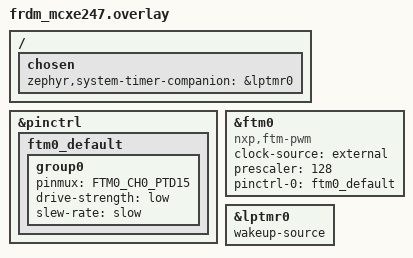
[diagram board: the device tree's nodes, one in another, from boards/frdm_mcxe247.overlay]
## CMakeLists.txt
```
# Copyright 2026 NXP
# SPDX-License-Identifier: Apache-2.0

cmake_minimum_required(VERSION 3.20.0)

# Pulls in this repository as a Zephyr module, which is what makes lib/pm_test,
# include/pm_test and the snippets/pm-* snippets available. Nothing has to be
# passed on the command line: `-S pm-<layer>` is the whole interface.
list(APPEND EXTRA_ZEPHYR_MODULES ${CMAKE_CURRENT_LIST_DIR}/../..)

find_package(Zephyr REQUIRED HINTS $ENV{ZEPHYR_BASE})
project(ftm_device_pm)

# The suite, the register view, and the control test that every layer runs.
target_sources(app PRIVATE src/main.c src/ftm.c src/test_control.c)

# One file per layer. A layer file is the only place that layer claims live, so a
# build for a layer contains no code belonging to any other.
#
# There is no dpd scenario: no SoC with an FTM declares a suspend-to-ram power
# state, so pm-dpd would not even configure. See README.md.
target_sources_ifdef(CONFIG_PM_TEST_LAYER_DEVICE     app PRIVATE src/test_device.c)
target_sources_ifdef(CONFIG_PM_TEST_LAYER_RUNTIME    app PRIVATE src/test_runtime.c)
target_sources_ifdef(CONFIG_PM_TEST_LAYER_SYSTEM     app PRIVATE src/test_system.c)
target_sources_ifdef(CONFIG_PM_TEST_LAYER_SYSMANAGED app PRIVATE src/test_lowpower.c)
```

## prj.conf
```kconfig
# Copyright 2026 NXP
# SPDX-License-Identifier: Apache-2.0
#
# Layer-independent configuration only. The PM symbols come from the layer, which
# comes from the pm-* snippet; see lib/pm_test/Kconfig and docs/pm-layers.md.

CONFIG_ZTEST=y
CONFIG_PM_TEST=y

CONFIG_PWM=y

# The 1024-byte ztest and main stack defaults are not enough for this case on a
# Cortex-M0+ with picolibc: the TC_PRINT in ftm_report_hw formats six arguments,
# and the overflow surfaces as a spurious assertion failure whose own report then
# panics inside zassert_vprint with k_current_get called pre-kernel. Observed on
# frdm_ke17z.
CONFIG_ZTEST_STACK_SIZE=3072
CONFIG_MAIN_STACK_SIZE=2048

# Driver logging at info level, immediate: the run ends with interrupts locked so
# that the core cannot park in WFI, and a deferred log would never be flushed.
# include/pm_test/layer.h asserts this pairing.
CONFIG_LOG=y
CONFIG_LOG_MODE_IMMEDIATE=y
CONFIG_PWM_LOG_LEVEL_INF=y
```

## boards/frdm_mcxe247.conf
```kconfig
# Copyright 2026 NXP
# SPDX-License-Identifier: Apache-2.0

CONFIG_IDLE_STACK_SIZE=1024
```

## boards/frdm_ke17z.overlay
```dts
/*
 * SPDX-FileCopyrightText: Copyright 2026 NXP
 *
 * SPDX-License-Identifier: Apache-2.0
 *
 */

/*
 * The ke1xz lptmr0 clocks the prescaler from a 128 kHz source and bypasses it,
 * so the 16-bit counter wraps at 0.512 s -- less than the 2 s the sysmanaged
 * layer forces. Divide by 8 instead: 16 kHz puts the range at 4.096 s, and one
 * tick at 62.5 us is still finer than the 140 us exit latency the node declares,
 * so the forced transition is timed by a single alarm rather than chopped into
 * re-armed pieces.
 */
&lptmr0 {
	/delete-property/ prescale-glitch-filter-bypass;
	prescale-glitch-filter = <2>;
};
```

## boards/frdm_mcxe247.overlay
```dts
/*
 * SPDX-FileCopyrightText: Copyright 2026 NXP
 *
 * SPDX-License-Identifier: Apache-2.0
 *
 */

&pinctrl {
	ftm0_default: ftm0_default {
		group0 {
			pinmux = <FTM0_CH0_PTD15>;
			drive-strength = "low";
			slew-rate = "slow";
		};
	};
};

&ftm0 {
	status = "okay";
	compatible = "nxp,ftm-pwm";
	clock-source = "external";
	prescaler = <128>;
	#pwm-cells = <3>;
	pinctrl-0 = <&ftm0_default>;
	pinctrl-names = "default";
};

/*
 * MCXE24x leaves lptmr0 disabled and unmarked, so without this the sysmanaged
 * layer would have no timed wake source and the forced Deep Sleep would never
 * end.
 */
&lptmr0 {
	status = "okay";
	wakeup-source;
};

/ {
	chosen {
		zephyr,system-timer-companion = &lptmr0;
	};
};
```

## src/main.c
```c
/*
 * SPDX-FileCopyrightText: Copyright 2026 NXP
 *
 * SPDX-License-Identifier: Apache-2.0
 */

/**
 * @file
 * @brief FTM device-PM suite: the suite hooks, and nothing else.
 *
 * Which layer this build tests, and therefore which src/test_*.c is compiled in,
 * is decided by the pm-* snippet on the command line. See docs/pm-layers.md.
 */

#include <zephyr/ztest.h>

#include <pm_test/layer.h>
#include <pm_test/state.h>

#include "ftm.h"

static void *ftm_pm_setup(void)
{
	(void)pm_test_setup();
	ftm_report_configuration();

	FTM_FOREACH_CASE(c) {
		pm_test_note_state(c->dev, "at boot");
		ftm_report_hw(c, "at boot");
	}

	return NULL;
}

static void ftm_pm_before(void *fixture)
{
	ARG_UNUSED(fixture);

	FTM_FOREACH_CASE(c) {
		zassert_true(device_is_ready(c->dev), "%s is not ready", c->dev->name);
	}
}

ZTEST_SUITE(ftm_pm, NULL, ftm_pm_setup, ftm_pm_before, NULL, NULL);
```

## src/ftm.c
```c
/*
 * SPDX-FileCopyrightText: Copyright 2026 NXP
 *
 * SPDX-License-Identifier: Apache-2.0
 */

/**
 * @file
 * @brief The FTM wiring, and the hardware truths this case asserts on.
 */

#include <errno.h>
#include <zephyr/devicetree.h>
#include <zephyr/kernel.h>
#include <zephyr/sys/util.h>
#include <zephyr/tc_util.h>

#include <fsl_clock.h>
#include <fsl_ftm.h>
#include <soc.h>

#include "ftm.h"

#define FTM_ENTRY(node_id)                                                                         \
	{                                                                                          \
		.dev = DEVICE_DT_GET(node_id),                                                     \
		.base = (uintptr_t)DT_REG_ADDR(node_id),                                           \
	},

const struct ftm_case ftm_cases[FTM_CASE_COUNT] = {
	DT_FOREACH_STATUS_OKAY(nxp_ftm_pwm, FTM_ENTRY)
};

static FTM_Type *ftm_base(const struct ftm_case *c)
{
	return (FTM_Type *)c->base;
}

/*
 * The instance number, from the register address rather than from the devicetree
 * clocks cell. The first clocks entry of an FTM node names the counter clock
 * source, not the gate -- frdm_ke17z points it at SCG and frdm_mcxe247 at PCC --
 * so it cannot name the gate for both. FTM_BASE_PTRS is the HAL own list and is
 * right on every part it serves.
 */
static bool ftm_instance_of(const struct ftm_case *c, uint32_t *instance)
{
	FTM_Type *const bases[] = FTM_BASE_PTRS;

	for (uint32_t i = 0U; i < ARRAY_SIZE(bases); i++) {
		if (bases[i] == ftm_base(c)) {
			*instance = i;
			return true;
		}
	}

	return false;
}

/*
 * kCLOCK_Ftm<n> is the absolute address of the PCC register that holds this
 * instance gate, which is how the HAL CLOCK_EnableClock() and
 * CLOCK_DisableClock() reach it. Guarded by the HAL instance count rather than
 * by the devicetree: MKE17Z stops at FTM2 and naming kCLOCK_Ftm3 there does not
 * compile, while MCXE24x has eight.
 */
static bool ftm_gate_of(const struct ftm_case *c, clock_ip_name_t *gate)
{
	uint32_t instance;

	if (!ftm_instance_of(c, &instance)) {
		return false;
	}

	switch (instance) {
	case 0:
		*gate = kCLOCK_Ftm0;
		break;
#if FSL_FEATURE_SOC_FTM_COUNT > 1
	case 1:
		*gate = kCLOCK_Ftm1;
		break;
#endif
#if FSL_FEATURE_SOC_FTM_COUNT > 2
	case 2:
		*gate = kCLOCK_Ftm2;
		break;
#endif
#if FSL_FEATURE_SOC_FTM_COUNT > 3
	case 3:
		*gate = kCLOCK_Ftm3;
		break;
#endif
#if FSL_FEATURE_SOC_FTM_COUNT > 4
	case 4:
		*gate = kCLOCK_Ftm4;
		break;
#endif
#if FSL_FEATURE_SOC_FTM_COUNT > 5
	case 5:
		*gate = kCLOCK_Ftm5;
		break;
#endif
#if FSL_FEATURE_SOC_FTM_COUNT > 6
	case 6:
		*gate = kCLOCK_Ftm6;
		break;
#endif
#if FSL_FEATURE_SOC_FTM_COUNT > 7
	case 7:
		*gate = kCLOCK_Ftm7;
		break;
#endif
	default:
		return false;
	}

	return true;
}

bool ftm_gate_observable(const struct ftm_case *c)
{
	clock_ip_name_t gate;

	return ftm_gate_of(c, &gate);
}

bool ftm_gate_is_open(const struct ftm_case *c)
{
	clock_ip_name_t gate;

	if (!ftm_gate_of(c, &gate)) {
		return false;
	}

	/* The gate enum is the register address, and unlike the LPC-style write-only
	 * SET/CLR aliases this register is readable, so the gate can be read back
	 * directly.
	 */
	return (*(const volatile uint32_t *)(uintptr_t)gate & PCC_CLKCFG_CGC_MASK) != 0U;
}

void ftm_gate_open(const struct ftm_case *c)
{
	clock_ip_name_t gate;

	if (ftm_gate_of(c, &gate)) {
		CLOCK_EnableClock(gate);
	}
}

void ftm_gate_close(const struct ftm_case *c)
{
	clock_ip_name_t gate;

	if (ftm_gate_of(c, &gate)) {
		CLOCK_DisableClock(gate);
	}
}

void ftm_image_read(const struct ftm_case *c, struct ftm_image *img)
{
	FTM_Type *base = ftm_base(c);

	img->mod = base->MOD;
	img->cnv = base->CONTROLS[FTM_PWM_CHANNEL].CnV;
	img->sc = base->SC;
}

bool ftm_image_equal(const struct ftm_image *a, const struct ftm_image *b)
{
	return (a->mod == b->mod) && (a->cnv == b->cnv) && (a->sc == b->sc);
}

void ftm_clobber(const struct ftm_case *c, struct ftm_image *clobbered)
{
	FTM_Type *base = ftm_base(c);
	bool was_open = ftm_gate_is_open(c);

	/* The registers cannot be written while the peripheral is unclocked, and this is
	 * called from a layer where the driver has already gated it.
	 */
	ftm_gate_open(c);

	/* SC last: clearing CLKS is what stops the counter, and the writes above want
	 * a clocked peripheral.
	 */
	base->MOD = 0U;
	base->CONTROLS[FTM_PWM_CHANNEL].CnV = 0U;
	base->SC = 0U;

	ftm_image_read(c, clobbered);

	if (!was_open) {
		ftm_gate_close(c);
	}
}

bool ftm_running(const struct ftm_case *c)
{
	return (ftm_base(c)->SC & FTM_SC_CLKS_MASK) != 0U;
}

bool ftm_advances(const struct ftm_case *c)
{
	uint32_t first = ftm_base(c)->CNT;
	uint32_t second;

	/*
	 * Busy-waited rather than slept: at the slowest counter clock either board
	 * attaches this is still several ticks, and a sleep would let the idle thread
	 * enter a power state in the layers that have one.
	 */
	k_busy_wait(2000);

	second = ftm_base(c)->CNT;

	return first != second;
}

int ftm_set_pwm(const struct ftm_case *c)
{
	return pwm_set_cycles(c->dev, FTM_PWM_CHANNEL, FTM_PWM_PERIOD_CYCLES,
			      FTM_PWM_PULSE_CYCLES, 0);
}

int ftm_release_pwm(const struct ftm_case *c)
{
	return pwm_set_cycles(c->dev, FTM_PWM_CHANNEL, 0U, 0U, 0);
}

int ftm_start_and_verify(const struct ftm_case *c)
{
	int err = ftm_set_pwm(c);

	if (err != 0) {
		return err;
	}

	return ftm_advances(c) ? 0 : -ESTALE;
}

void ftm_report_configuration(void)
{
	TC_PRINT("%u FTM instance(s) under test\n", (unsigned int)FTM_CASE_COUNT);

	FTM_FOREACH_CASE(c) {
		uint32_t instance = 0U;
		uint64_t cycles = 0U;

		(void)ftm_instance_of(c, &instance);
		(void)pwm_get_cycles_per_sec(c->dev, FTM_PWM_CHANNEL, &cycles);

		TC_PRINT("  %s: FTM%u at %p, %u Hz counter clock, channel %u, gate %s\n",
			 c->dev->name, (unsigned int)instance, (void *)c->base,
			 (unsigned int)cycles, (unsigned int)FTM_PWM_CHANNEL,
			 ftm_gate_observable(c) ? "observable"
						      : "NOT observable on this SoC");
	}
}

void ftm_report_hw(const struct ftm_case *c, const char *when)
{
	if (!ftm_gate_observable(c)) {
		TC_PRINT("hw(%s, %s) gate not observable on this SoC\n", when, c->dev->name);
		return;
	}

	if (!ftm_gate_is_open(c)) {
		/* No register read: an unclocked peripheral does not answer. */
		TC_PRINT("hw(%s, %s) gate=0, registers not read\n", when, c->dev->name);
		return;
	}

	struct ftm_image img;

	ftm_image_read(c, &img);
	TC_PRINT("hw(%s, %s) gate=1 SC=0x%08x MOD=0x%08x CnV%u=0x%08x CNT=0x%08x\n", when,
		 c->dev->name, img.sc, img.mod, (unsigned int)FTM_PWM_CHANNEL, img.cnv,
		 ((FTM_Type *)c->base)->CNT);
}
```

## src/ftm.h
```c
/*
 * SPDX-FileCopyrightText: Copyright 2026 NXP
 *
 * SPDX-License-Identifier: Apache-2.0
 */

/**
 * @file
 * @brief What every layer of the FTM case needs from the hardware.
 *
 * Three things are observed.
 *
 * The peripheral clock gate, read out of the PCC rather than out of an FTM
 * register: an FTM register only answers while the peripheral is clocked, and whether
 * it is clocked is the question. Gating that clock is the whole of what SUSPEND
 * does for power.
 *
 * The register image of a running PWM: MOD holds the period and
 * CONTROLS[ch].CnV the pulse width, and nothing else in the peripheral carries them.
 * This is what tells a restored FTM from one that came back from reset. Both read
 * zero out of reset and non-zero once a consumer has asked for a waveform.
 *
 * CNT advancing, which is the control: an FTM takes its counter clock through a
 * source and a prescaler that the board devicetree picks rather than this driver,
 * so a register image that came back perfectly while the clock source did not
 * would read as restored and still not count.
 *
 * What is not observed is the waveform on the pin. An FTM has no completion event
 * a test could wait on, so proving the output really toggles needs an external
 * loopback -- that is what tests/drivers/pwm/pwm_loopback is for. See README.md.
 */

#ifndef FTM_PM_H_
#define FTM_PM_H_

#include <stdbool.h>
#include <stdint.h>
#include <zephyr/device.h>
#include <zephyr/devicetree.h>
#include <zephyr/drivers/pwm.h>

#if !DT_HAS_COMPAT_STATUS_OKAY(nxp_ftm_pwm)
#error "No nxp,ftm-pwm node is enabled on this board"
#endif

#if !defined(CONFIG_PWM_MCUX_FTM)
#error "CONFIG_PWM_MCUX_FTM is not enabled, so there is no driver to test"
#endif

/**
 * @brief The channel every test drives.
 *
 * Channel 0 exists on every instance and is pin-muxed on both board targets this
 * case covers, so the register image below corresponds to a pin that is really
 * driven even though no test asserts on its level.
 */
#define FTM_PWM_CHANNEL 0U

/**
 * @brief The period and pulse every test asks for, in counter ticks.
 *
 * Asked for in ticks rather than nanoseconds so that the register image is the
 * same on both boards: the counter clock differs between them, and MOD has to stay
 * inside 16 bits whatever it is.
 */
#define FTM_PWM_PERIOD_CYCLES 10000U
#define FTM_PWM_PULSE_CYCLES  5000U

/** How many enabled nxp,ftm-pwm instances this build covers. */
#define FTM_PM_COUNT_ONE(node_id) +1
#define FTM_CASE_COUNT (0 DT_FOREACH_STATUS_OKAY(nxp_ftm_pwm, FTM_PM_COUNT_ONE))

/** One FTM instance under test. */
struct ftm_case {
	const struct device *dev;
	/** Register block, for the registers a running PWM lives in. */
	uintptr_t base;
};

extern const struct ftm_case ftm_cases[FTM_CASE_COUNT];

/** @brief Iterate the instances. */
#define FTM_FOREACH_CASE(c)                                                                        \
	for (const struct ftm_case *c = &ftm_cases[0];                                             \
	     c < &ftm_cases[FTM_CASE_COUNT]; c++)

/**
 * @brief True when this SoC HAL names a clock gate for @p c.
 *
 * An instance whose gate cannot be named is reported and asserted nothing about,
 * rather than passing quietly.
 */
bool ftm_gate_observable(const struct ftm_case *c);

/** @brief True while the instance peripheral clock gate is open. */
bool ftm_gate_is_open(const struct ftm_case *c);

/** @brief Open the gate behind the driver back, so a clobber can be written. */
void ftm_gate_open(const struct ftm_case *c);

/** @brief Close it again, leaving the peripheral as a suspend left it. */
void ftm_gate_close(const struct ftm_case *c);

/**
 * @brief The registers a running PWM lives in.
 *
 * Only meaningful while the peripheral is clocked; every caller here reads it with the
 * gate open.
 */
struct ftm_image {
	uint32_t mod;
	uint32_t cnv;
	uint32_t sc;
};

/** @brief Sample @ref ftm_image. */
void ftm_image_read(const struct ftm_case *c, struct ftm_image *img);

/** @brief True when two images are the same. */
bool ftm_image_equal(const struct ftm_image *a, const struct ftm_image *b);

/**
 * @brief Overwrite the running-PWM registers with a cleared image.
 *
 * What stands in for a power cycle in a layer where nothing really cut power, so
 * that a restore has something to put back. Takes care of the clock gate itself
 * and leaves it as it found it.
 *
 * @param c         instance to clobber
 * @param clobbered read back after the write, so a caller can prove the clobber
 *                  took
 */
void ftm_clobber(const struct ftm_case *c, struct ftm_image *clobbered);

/** @brief True while SC[CLKS] says the counter is clocked. */
bool ftm_running(const struct ftm_case *c);

/** @brief True when two CNT reads a short wait apart differ. */
bool ftm_advances(const struct ftm_case *c);

/**
 * @brief Ask for the waveform every test uses.
 *
 * @return 0, or negative errno from pwm_set_cycles().
 */
int ftm_set_pwm(const struct ftm_case *c);

/**
 * @brief Hand the channel back, so the driver has a reason to drop its lock.
 *
 * A period of 0 is what the driver takes as "drive nothing out". It is the only
 * way through the PWM API to undo @ref ftm_set_pwm while the device stays active,
 * which is what a counter gets from counter_stop().
 *
 * @return 0, or negative errno from pwm_set_cycles().
 */
int ftm_release_pwm(const struct ftm_case *c);

/**
 * @brief Ask for the waveform and check that the counter is actually running.
 *
 * @return 0, negative errno from the PWM API, or -ESTALE when CNT did not move.
 */
int ftm_start_and_verify(const struct ftm_case *c);

/** @brief Print what the devicetree asked for, once, from the suite setup. */
void ftm_report_configuration(void);

/**
 * @brief Print the gate and, when the gate is open, the register image.
 *
 * Safe to call with the gate closed: it prints the gate and says the registers
 * were not read rather than faulting on an unclocked peripheral.
 *
 * @param when short label for where in the sequence this is, e.g. "before".
 */
void ftm_report_hw(const struct ftm_case *c, const char *when);

#endif /* FTM_PM_H_ */
```

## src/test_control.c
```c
/*
 * SPDX-FileCopyrightText: Copyright 2026 NXP
 *
 * SPDX-License-Identifier: Apache-2.0
 */

/**
 * @file
 * @brief The control: this case really does drive the FTM.
 *
 * Compiled into every layer. If this fails, no verdict from the layer under test
 * means anything.
 *
 * Two claims: that the counter counts once a waveform has been asked for, and that
 * the request leaves a register image distinguishable from one at reset. Every
 * later layer tells "restored" from "came back from reset" by comparing against
 * that image.
 */

#include <zephyr/pm/device_runtime.h>
#include <zephyr/ztest.h>

#include "ftm.h"

ZTEST(ftm_pm, test_control_drives_the_pwm)
{
	FTM_FOREACH_CASE(c) {
		struct ftm_image running;
		bool held = false;
		int set_rc;
		bool advanced;
		bool clocked;

		/*
		 * Under runtime PM the device boots suspended and this driver takes no
		 * reference of its own, so the control has to ask for it. That an
		 * unwrapped call is refused is test_runtime.c's claim, not a premise of
		 * the control.
		 */
		if (pm_device_runtime_is_enabled(c->dev)) {
			zassert_ok(pm_device_runtime_get(c->dev),
				   "%s: could not resume the device for the control",
				   c->dev->name);
			held = true;
		}

		/*
		 * Every register read is taken while the reference is still held. The
		 * put() below gates the peripheral clock, and reading a gated FTM register
		 * on these parts is a bus fault rather than a stale value.
		 */
		set_rc = ftm_set_pwm(c);
		advanced = ftm_advances(c);
		clocked = ftm_running(c);
		ftm_image_read(c, &running);
		ftm_report_hw(c, "control");

		if (held) {
			/* Before the assertions: a failure must not leak the reference. */
			(void)pm_device_runtime_put(c->dev);
		}

		zassert_ok(set_rc, "%s: pwm_set_cycles() failed (%d)", c->dev->name, set_rc);
		zassert_true(advanced, "%s: CNT did not advance with a waveform set",
			     c->dev->name);

		/*
		 * MOD and CnV are the only register state in this peripheral that a restore
		 * can be seen to put back: both read zero out of reset, so an image
		 * where they are still zero makes every later comparison a
		 * zero-against-zero.
		 */
		zassert_not_equal(running.mod, 0U, "%s: MOD is 0 with a waveform set",
				  c->dev->name);
		zassert_not_equal(running.cnv, 0U, "%s: CnV%u is 0 with a waveform set",
				  c->dev->name, (unsigned int)FTM_PWM_CHANNEL);
		zassert_true(clocked, "%s: SC[CLKS] is clear with a waveform set",
			     c->dev->name);
	}
}
```

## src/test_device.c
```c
/*
 * SPDX-FileCopyrightText: Copyright 2026 NXP
 *
 * SPDX-License-Identifier: Apache-2.0
 */

/**
 * @file
 * @brief The device layer: the driver PM callbacks, driven directly.
 *
 * Two tests, for the two halves of the callback. The first is the SUSPEND/RESUME
 * round trip, which owns the clock gate. The second is TURN_OFF/TURN_ON, which
 * owns the register block -- and since nothing in this layer really cut power to
 * it, the registers are clobbered by hand so that the restore has something to put
 * back.
 *
 * There is no dpd layer to ask what a real power cycle does, because no SoC with
 * an FTM declares a suspend-to-ram state. The clobber stands in for one: the replay
 * is exercised from an arbitrarily corrupted register image rather than from one
 * that merely survived a clock gate.
 *
 * Note which action is expected to bring the peripheral up. This driver does nothing
 * in TURN_ON and configures from RESUME, so that an instance which boots
 * SUSPENDED under runtime PM boots with its clock genuinely gated instead of
 * running behind a PM state that says otherwise. No FTM node is on a power domain
 * either, so TURN_ON never arrives at run time at all and a bring-up placed there
 * would be dead code. The second test asserts that split.
 */

#include <zephyr/pm/device.h>
#include <zephyr/ztest.h>

#include <pm_test/state.h>

#include "ftm.h"

ZTEST(ftm_pm, test_device_suspend_resume)
{
	FTM_FOREACH_CASE(c) {
		struct ftm_image running;
		struct ftm_image after;
		int err;

		if (!ftm_gate_observable(c)) {
			TC_PRINT("%s: clock gate not observable, nothing asserted\n",
				 c->dev->name);
			continue;
		}

		/* No runtime PM in this layer, so pm_device_driver_init() resumed it. */
		zassert_pm_state(c->dev, PM_DEVICE_STATE_ACTIVE);
		zassert_true(ftm_gate_is_open(c),
			     "%s: gate closed while PM reports ACTIVE", c->dev->name);

		zassert_ok(ftm_start_and_verify(c), "%s: the counter did not run", c->dev->name);
		ftm_image_read(c, &running);
		ftm_report_hw(c, "before-suspend");

		zassert_ok(pm_device_action_run(c->dev, PM_DEVICE_ACTION_SUSPEND),
			   "%s: SUSPEND action rejected", c->dev->name);
		zassert_pm_state(c->dev, PM_DEVICE_STATE_SUSPENDED);
		ftm_report_hw(c, "after-suspend");

		/*
		 * The claim of this layer: the peripheral is no longer clocked. Nothing is read
		 * out of it here -- an unclocked peripheral does not answer, and reading it to
		 * find out whether it is clocked is the one thing that cannot be done.
		 */
		zassert_false(ftm_gate_is_open(c), "%s: clock gate still open after SUSPEND",
			      c->dev->name);

		zassert_ok(pm_device_action_run(c->dev, PM_DEVICE_ACTION_RESUME),
			   "%s: RESUME action rejected", c->dev->name);
		zassert_pm_state(c->dev, PM_DEVICE_STATE_ACTIVE);
		ftm_image_read(c, &after);
		ftm_report_hw(c, "after-resume");

		zassert_true(ftm_gate_is_open(c), "%s: gate still closed after RESUME",
			     c->dev->name);

		/*
		 * The waveform the consumer asked for is back without the consumer asking
		 * again, and the counter it was programmed against is running.
		 */
		zassert_true(ftm_image_equal(&after, &running),
			     "%s: RESUME left SC=0x%08x MOD=0x%08x CnV=0x%08x, want "
			     "0x%08x/0x%08x/0x%08x", c->dev->name, after.sc, after.mod,
			     after.cnv, running.sc, running.mod, running.cnv);
		zassert_true(ftm_advances(c), "%s: the counter is not running after RESUME",
			     c->dev->name);

		/* A redundant action must be refused, not obeyed and not fatal. */
		err = pm_device_action_run(c->dev, PM_DEVICE_ACTION_RESUME);
		zassert_equal(err, -EALREADY, "%s: second RESUME returned %d, want -EALREADY",
			      c->dev->name, err);
	}
}

ZTEST(ftm_pm, test_device_resume_rebuilds_the_register_block)
{
	FTM_FOREACH_CASE(c) {
		struct ftm_image running;
		struct ftm_image clobbered;
		struct ftm_image after_resume;
		bool gate_after_turn_on;
		int suspend_rc;
		int turn_off_rc;
		int turn_on_rc;
		int resume_rc;

		if (!ftm_gate_observable(c)) {
			TC_PRINT("%s: clock gate not observable, nothing asserted\n",
				 c->dev->name);
			continue;
		}

		zassert_pm_state(c->dev, PM_DEVICE_STATE_ACTIVE);
		zassert_ok(ftm_start_and_verify(c), "%s: the counter did not run", c->dev->name);
		ftm_image_read(c, &running);

		/*
		 * Collected in one go and asserted afterwards, so that a failure cannot hand
		 * the next test a device the core still records as OFF.
		 */
		suspend_rc = pm_device_action_run(c->dev, PM_DEVICE_ACTION_SUSPEND);

		ftm_clobber(c, &clobbered);

		turn_off_rc = pm_device_action_run(c->dev, PM_DEVICE_ACTION_TURN_OFF);

		turn_on_rc = pm_device_action_run(c->dev, PM_DEVICE_ACTION_TURN_ON);
		gate_after_turn_on = ftm_gate_is_open(c);

		resume_rc = pm_device_action_run(c->dev, PM_DEVICE_ACTION_RESUME);
		ftm_image_read(c, &after_resume);
		ftm_report_hw(c, "after-resume");

		zassert_ok(suspend_rc, "%s: SUSPEND rejected (%d)", c->dev->name, suspend_rc);
		zassert_ok(turn_off_rc, "%s: TURN_OFF rejected (%d)", c->dev->name, turn_off_rc);
		zassert_ok(turn_on_rc, "%s: TURN_ON rejected (%d)", c->dev->name, turn_on_rc);
		zassert_ok(resume_rc, "%s: RESUME rejected (%d)", c->dev->name, resume_rc);
		zassert_pm_state(c->dev, PM_DEVICE_STATE_ACTIVE);

		/* Before anything else: a clobber that did not take would make the restore
		 * assertion below answerable without the peripheral ever having been disturbed.
		 */
		zassert_false(ftm_image_equal(&clobbered, &running),
			      "%s: the clobber did not take", c->dev->name);

		/*
		 * TURN_ON returns with the core about to record the device as suspended, so
		 * a peripheral left clocked would be one running behind a PM state that says
		 * it is not. Bringing it back is RESUME's job, and it has to bring back the
		 * run-time image rather than a fresh devicetree configuration.
		 */
		zassert_false(gate_after_turn_on, "%s: TURN_ON opened the clock gate",
			      c->dev->name);
		zassert_true(ftm_gate_is_open(c), "%s: RESUME left the clock gate closed",
			     c->dev->name);
		zassert_true(ftm_image_equal(&after_resume, &running),
			     "%s: RESUME left SC=0x%08x MOD=0x%08x CnV=0x%08x, want "
			     "0x%08x/0x%08x/0x%08x", c->dev->name, after_resume.sc,
			     after_resume.mod, after_resume.cnv, running.sc, running.mod,
			     running.cnv);
		zassert_true(ftm_advances(c), "%s: the counter is not running after RESUME",
			     c->dev->name);
	}
}
```

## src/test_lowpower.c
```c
/*
 * SPDX-FileCopyrightText: Copyright 2026 NXP
 *
 * SPDX-License-Identifier: Apache-2.0
 */

/**
 * @file
 * @brief The sysmanaged layer: the device sweep across one transition.
 *
 * One layer, not two: no SoC with an FTM declares a suspend-to-ram state, so there
 * is no dpd build for this file to serve as well.
 *
 * That makes this layer carry the claim dpd would have carried on a part that has
 * one. The driver gates the peripheral clock from SUSPEND -- FTM_Deinit() halts the
 * counter and then gates it -- and brings the peripheral up from scratch in RESUME,
 * FTM_Init() and all. So the register image is unreachable for the whole of the
 * transition whether or not the silicon cut power, and the sweep RESUME has to
 * rebuild the waveform from the image the driver kept in RAM rather than from
 * anything the hardware remembered. A driver with no restore path fails here.
 *
 * What is asserted after the transition is behavioural as well as register-level:
 * that the counter counts again. An FTM takes its counter clock through a source
 * and prescaler the board devicetree picks rather than this driver, so a register
 * image that came back perfectly while the clock source did not would look
 * restored and still not count.
 */

#include <zephyr/pm/device.h>
#include <zephyr/ztest.h>

#include <pm_test/lowpower.h>
#include <pm_test/state.h>

#include "ftm.h"

ZTEST(ftm_pm, test_sweep_across_transition)
{
	FTM_FOREACH_CASE(c) {
		struct ftm_image running;
		struct ftm_image after;
		bool gate_after;

		/* No runtime PM in this layer, so the sweep is the only thing that will
		 * suspend the device.
		 */
		zassert_pm_state(c->dev, PM_DEVICE_STATE_ACTIVE);

		zassert_ok(ftm_start_and_verify(c),
			   "%s: the counter did not run before the transition", c->dev->name);
		ftm_image_read(c, &running);
		ftm_report_hw(c, "before");

		pm_test_enter_transition();

		/* Sampled before the console is revived: reviving it takes time, and the
		 * question is what the peripheral looked like the moment the sweep handed it
		 * back.
		 */
		gate_after = ftm_gate_is_open(c);
		if (gate_after) {
			ftm_image_read(c, &after);
		}

		pm_test_console_resume(PM_TEST_CONSOLE_REINIT_PINMUX);
		TC_PRINT("resumed from %s\n", PM_TEST_TRANSITION_NAME);
		ftm_report_hw(c, "after-resume");

		zassert_pm_state(c->dev, PM_DEVICE_STATE_ACTIVE);

		if (!ftm_gate_observable(c)) {
			TC_PRINT("%s: clock gate not observable, register claims skipped\n",
				 c->dev->name);
		} else {
			/*
			 * The gate first: without it the register comparison below would be
			 * reading an unclocked peripheral, and restored would be whatever the bus
			 * returns.
			 */
			zassert_true(gate_after,
				     "%s: the clock gate was not re-opened across the transition",
				     c->dev->name);
			zassert_true(ftm_image_equal(&after, &running),
				     "%s: the waveform did not survive the transition: "
				     "SC=0x%08x MOD=0x%08x CnV=0x%08x, want 0x%08x/0x%08x/0x%08x",
				     c->dev->name, after.sc, after.mod, after.cnv, running.sc,
				     running.mod, running.cnv);
		}

		/* And the peripheral has to work, not just read back right. */
		zassert_true(ftm_advances(c),
			     "%s: the counter is not counting after the transition",
			     c->dev->name);
	}
}
```

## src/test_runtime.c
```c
/*
 * SPDX-FileCopyrightText: Copyright 2026 NXP
 *
 * SPDX-License-Identifier: Apache-2.0
 */

/**
 * @file
 * @brief The runtime layer: the consumer owns the waveform, and says so with a
 *        reference.
 *
 * This driver takes no runtime PM reference of its own. A PWM output runs for as
 * long as the application wants a waveform, and there is no completion event a
 * put() could hang on, so wrapping each API call in its own get/put would stop
 * the output the moment the call returned. The reference is the consumer's.
 *
 * What this layer catches is the boot state. pm_device_driver_init() runs TURN_ON
 * and then stops short of RESUME when runtime PM is about to own the device, so a
 * driver that brings the peripheral up in TURN_ON boots it clocked while the core
 * records it as SUSPENDED. This driver brings the peripheral up in RESUME for that
 * reason, and the first test below is the check.
 *
 * Two tests. The first has to run first: it reads the state the device booted in,
 * and the second leaves it suspended.
 */

#include <zephyr/pm/device.h>
#include <zephyr/pm/device_runtime.h>
#include <zephyr/ztest.h>

#include <pm_test/state.h>

#include "ftm.h"

ZTEST(ftm_pm, test_runtime_boots_without_a_consumer)
{
	FTM_FOREACH_CASE(c) {
		enum pm_device_state state;

		zassert_true(pm_device_runtime_is_enabled(c->dev),
			     "%s: runtime PM is not enabled on this device", c->dev->name);

		/*
		 * Two boot states are legal. Without a power domain the device lands in
		 * SUSPENDED; with one it would land in OFF, because the domain is
		 * runtime-suspended before the FTM initialises and TURN_ON is skipped. No
		 * FTM node is on a domain today, so SUSPENDED is what these boards show.
		 */
		zassert_ok(pm_device_state_get(c->dev, &state),
			   "%s: pm_device_state_get() failed", c->dev->name);
		zassert_true((state == PM_DEVICE_STATE_SUSPENDED) ||
				     (state == PM_DEVICE_STATE_OFF),
			     "%s booted %s, want SUSPENDED or OFF under runtime PM",
			     c->dev->name, pm_device_state_str(state));

		if (!ftm_gate_observable(c)) {
			TC_PRINT("%s: clock gate not observable, nothing asserted\n",
				 c->dev->name);
			continue;
		}

		/* The claim. Nothing may be clocked before a consumer has asked for it. */
		zassert_false(ftm_gate_is_open(c),
			      "%s: clock gate open before any consumer took a reference",
			      c->dev->name);
	}
}

ZTEST(ftm_pm, test_runtime_reference_counting)
{
	FTM_FOREACH_CASE(c) {
		struct ftm_image running;
		struct ftm_image after;

		zassert_ok(pm_device_runtime_get(c->dev), "%s: runtime_get rejected",
			   c->dev->name);
		zassert_pm_state(c->dev, PM_DEVICE_STATE_ACTIVE);

		if (ftm_gate_observable(c)) {
			zassert_true(ftm_gate_is_open(c),
				     "%s: gate closed while PM reports ACTIVE", c->dev->name);
		}

		zassert_ok(ftm_start_and_verify(c),
			   "%s: the counter did not run under a held reference", c->dev->name);
		ftm_image_read(c, &running);

		/* A second reference must not be a second resume, and releasing it must not
		 * stop a waveform somebody else is still holding.
		 */
		zassert_ok(pm_device_runtime_get(c->dev), "%s: nested runtime_get rejected",
			   c->dev->name);
		zassert_ok(pm_device_runtime_put(c->dev), "%s: first runtime_put rejected",
			   c->dev->name);
		zassert_pm_state(c->dev, PM_DEVICE_STATE_ACTIVE);
		zassert_true(ftm_advances(c),
			     "%s: the counter stopped while a reference was held", c->dev->name);

		zassert_ok(pm_device_runtime_put(c->dev), "%s: last runtime_put rejected",
			   c->dev->name);
		zassert_pm_state(c->dev, PM_DEVICE_STATE_SUSPENDED);
		ftm_report_hw(c, "after-put");

		if (ftm_gate_observable(c)) {
			zassert_false(ftm_gate_is_open(c),
				      "%s: clock gate still open after the last runtime_put",
				      c->dev->name);
		}

		/*
		 * And the consumer gets its waveform back by taking the reference again,
		 * without asking for it a second time: what it programmed is the driver's
		 * own to remember across a suspend the consumer did not ask for.
		 */
		zassert_ok(pm_device_runtime_get(c->dev),
			   "%s: runtime_get after the put rejected", c->dev->name);
		ftm_image_read(c, &after);
		ftm_report_hw(c, "after-reget");

		zassert_true(ftm_image_equal(&after, &running),
			     "%s: the waveform did not come back with the reference: "
			     "SC=0x%08x MOD=0x%08x CnV=0x%08x, want 0x%08x/0x%08x/0x%08x",
			     c->dev->name, after.sc, after.mod, after.cnv, running.sc,
			     running.mod, running.cnv);
		zassert_true(ftm_advances(c),
			     "%s: the counter is not running after the reference came back",
			     c->dev->name);

		/* Left as it was found, so this test waveform does not outlive it. */
		zassert_ok(pm_device_runtime_put(c->dev), "%s: final runtime_put rejected",
			   c->dev->name);
	}
}
```

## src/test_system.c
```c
/*
 * SPDX-FileCopyrightText: Copyright 2026 NXP
 *
 * SPDX-License-Identifier: Apache-2.0
 */

/**
 * @file
 * @brief The system layer: the per-device power state constraint.
 *
 * The FTM node lists the states that stop it counting in
 * zephyr,disabling-power-states, declared by the SoC dtsi for every instance, and
 * the driver holds a policy constraint against exactly those states for as long as
 * a channel is driving an output. The window is not one API call -- a PWM output
 * has no completion event -- so the constraint follows the channel setup and the
 * device state together: a runtime-PM suspend that halts the counter hands the lock
 * back, a resume that restarts it takes it again, and a zero-period
 * pwm_set_cycles() hands the channel back and drops it. Without the release on
 * suspend, one pwm_set_cycles() would block those states for the rest of the run
 * even with no consumer left holding a reference.
 *
 * The helpers below iterate substates rather than asking about substate 0 alone.
 * Both SoCs this case runs on expose their deep-sleep family as three
 * suspend-to-idle substates -- the PSTOPO partial-stop options -- so asking only
 * about substate 0 would miss the locks on the other two.
 *
 * Two tests: that the lock matches what the node declares, appears only once there
 * is a running counter to protect, and goes away again when the channel is handed
 * back with a zero period; and that it follows the counter across a suspend and a
 * resume rather than being taken once and kept.
 */

#include <zephyr/pm/device_runtime.h>
#include <zephyr/pm/policy.h>
#include <zephyr/pm/state.h>
#include <zephyr/ztest.h>

#include <pm_test/lowpower.h>

#include "ftm.h"

/*
 * How many substates to ask about. Three covers the PSTOPO options these SoCs
 * declare; a state that has no such substate simply answers false for the ones it
 * does not have, so over-counting is free and under-counting is not.
 */
#define FTM_PM_SUBSTATE_COUNT 3U

/* How many state/substate pairs are locked right now, by anyone. */
static unsigned int locked_states(void)
{
	unsigned int locked = 0;

	for (enum pm_state state = PM_STATE_ACTIVE; state < PM_STATE_COUNT; state++) {
		for (uint8_t sub = 0U; sub < FTM_PM_SUBSTATE_COUNT; sub++) {
			locked += pm_policy_state_lock_is_active(state, sub) ? 1U : 0U;
		}
	}

	return locked;
}

/*
 * How many state/substate pairs this node declares as disabling. Pairs that are
 * listed but disabled in the devicetree are dropped from the generated table, so
 * this can legitimately be smaller than the list in the SoC dtsi. A zero means the
 * node carries no list at all, which is why the tests below guard on it.
 */
static unsigned int declared_states(const struct device *dev)
{
	unsigned int declared = 0;

	for (enum pm_state state = PM_STATE_ACTIVE; state < PM_STATE_COUNT; state++) {
		for (uint8_t sub = 0U; sub < FTM_PM_SUBSTATE_COUNT; sub++) {
			declared += pm_policy_device_is_disabling_state(dev, state, sub) ? 1U : 0U;
		}
	}

	return declared;
}

/* Locked pairs the node does not declare, or declared pairs left unlocked. */
static unsigned int constraint_mismatch(const struct device *dev)
{
	unsigned int mismatch = 0;

	for (enum pm_state state = PM_STATE_ACTIVE; state < PM_STATE_COUNT; state++) {
		for (uint8_t sub = 0U; sub < FTM_PM_SUBSTATE_COUNT; sub++) {
			bool locked = pm_policy_state_lock_is_active(state, sub);
			bool disabling = pm_policy_device_is_disabling_state(dev, state, sub);

			mismatch += (locked != disabling) ? 1U : 0U;
		}
	}

	return mismatch;
}

ZTEST(ftm_pm, test_system_constraint_covers_the_declared_states)
{
	FTM_FOREACH_CASE(c) {
		unsigned int before;
		unsigned int after_get;
		unsigned int while_running;
		unsigned int declared;
		unsigned int mismatch;
		unsigned int after_release;
		unsigned int after_suspend;
		bool running_after_get;
		int set_rc;
		int release_rc;

		declared = declared_states(c->dev);
		if (declared == 0U) {
			/* No state is declared to stop this instance, so there is no
			 * constraint to observe. Said rather than passed quietly.
			 */
			TC_PRINT("%s: declares no disabling power state, nothing asserted\n",
				 c->dev->name);
			continue;
		}

		pm_test_console_quiesce();
		before = locked_states();

		zassert_ok(pm_device_runtime_get(c->dev), "%s: runtime_get rejected",
			   c->dev->name);

		/*
		 * Resumed. Whether that restored a waveform depends on what an earlier test
		 * left in the driver's shadow state: a PWM has no configured-but-stopped
		 * state once pwm_set_cycles() has been called, so the resume replays it and
		 * the counter runs again. So the claim here is the invariant rather than a
		 * fixed number -- the lock is held exactly while a channel is driving an
		 * output, which a driver that took it unconditionally on resume fails
		 * whenever the peripheral comes back idle.
		 */
		pm_test_console_quiesce();
		running_after_get = ftm_running(c);
		after_get = locked_states();

		set_rc = ftm_start_and_verify(c);
		while_running = locked_states();
		mismatch = constraint_mismatch(c->dev);

		/*
		 * Handed back while the device is still active, which is the one release
		 * path that does not go through a suspend. A zero period is what asks for
		 * it; see mcux_ftm_release_channel() in the driver.
		 */
		release_rc = ftm_release_pwm(c);
		after_release = locked_states();

		/* Released before anything is asserted: a failure must not leave a lock
		 * behind, which would silently block those states for the rest of the run.
		 */
		(void)pm_device_runtime_put(c->dev);

		pm_test_console_quiesce();
		after_suspend = locked_states();

		zassert_equal(before, 0U, "%s: %u state(s) were already locked",
			      c->dev->name, before);
		zassert_ok(set_rc, "%s: the counter did not run (%d)", c->dev->name, set_rc);

		zassert_equal(after_get, running_after_get ? declared : 0U,
			      "%s: %u state(s) locked just after the resume, counter %s",
			      c->dev->name, after_get,
			      running_after_get ? "running" : "idle");
		zassert_equal(while_running, declared,
			      "%s: %u state(s) locked while counting, %u declared",
			      c->dev->name, while_running, declared);
		zassert_equal(mismatch, 0U,
			      "%s: %u state(s) whose lock does not match the node",
			      c->dev->name, mismatch);
		zassert_ok(release_rc, "%s: the channel could not be handed back (%d)",
			   c->dev->name, release_rc);
		zassert_equal(after_release, 0U,
			      "%s: %u state(s) still locked after the channel was handed back",
			      c->dev->name, after_release);
		zassert_equal(after_suspend, 0U,
			      "%s: %u state(s) still locked after the last put",
			      c->dev->name, after_suspend);
	}
}

ZTEST(ftm_pm, test_system_constraint_follows_the_counter)
{
	FTM_FOREACH_CASE(c) {
		unsigned int declared;
		unsigned int while_running;
		unsigned int while_suspended;
		unsigned int after_resume;
		unsigned int at_end;
		int set_rc;
		bool running_after_resume;

		declared = declared_states(c->dev);
		if (declared == 0U) {
			TC_PRINT("%s: declares no disabling power state, nothing asserted\n",
				 c->dev->name);
			continue;
		}

		pm_test_console_quiesce();

		zassert_ok(pm_device_runtime_get(c->dev), "%s: runtime_get rejected",
			   c->dev->name);
		set_rc = ftm_start_and_verify(c);
		while_running = locked_states();

		/* The last reference goes away, so the driver suspends and the counter
		 * halts -- and with it the reason for the lock.
		 */
		(void)pm_device_runtime_put(c->dev);
		pm_test_console_quiesce();
		while_suspended = locked_states();

		/*
		 * A resume restarts the waveform the consumer was running, so it has to
		 * take the protection back: without it the counter comes back running while
		 * the policy is free to enter a state that halts its clock.
		 */
		zassert_ok(pm_device_runtime_get(c->dev), "%s: second runtime_get rejected",
			   c->dev->name);
		running_after_resume = ftm_advances(c);
		after_resume = locked_states();

		(void)pm_device_runtime_put(c->dev);
		pm_test_console_quiesce();
		at_end = locked_states();

		zassert_ok(set_rc, "%s: the counter did not run (%d)", c->dev->name, set_rc);
		zassert_equal(while_running, declared,
			      "%s: %u state(s) locked while counting, %u declared",
			      c->dev->name, while_running, declared);
		zassert_equal(while_suspended, 0U,
			      "%s: %u state(s) still locked while suspended", c->dev->name,
			      while_suspended);
		zassert_true(running_after_resume,
			     "%s: the counter is not running after resume", c->dev->name);
		zassert_equal(after_resume, declared,
			      "%s: %u state(s) locked after the waveform came back, %u declared",
			      c->dev->name, after_resume, declared);
		zassert_equal(at_end, 0U,
			      "%s: %u state(s) leaked past the end of the test", c->dev->name,
			      at_end);
	}
}
```
